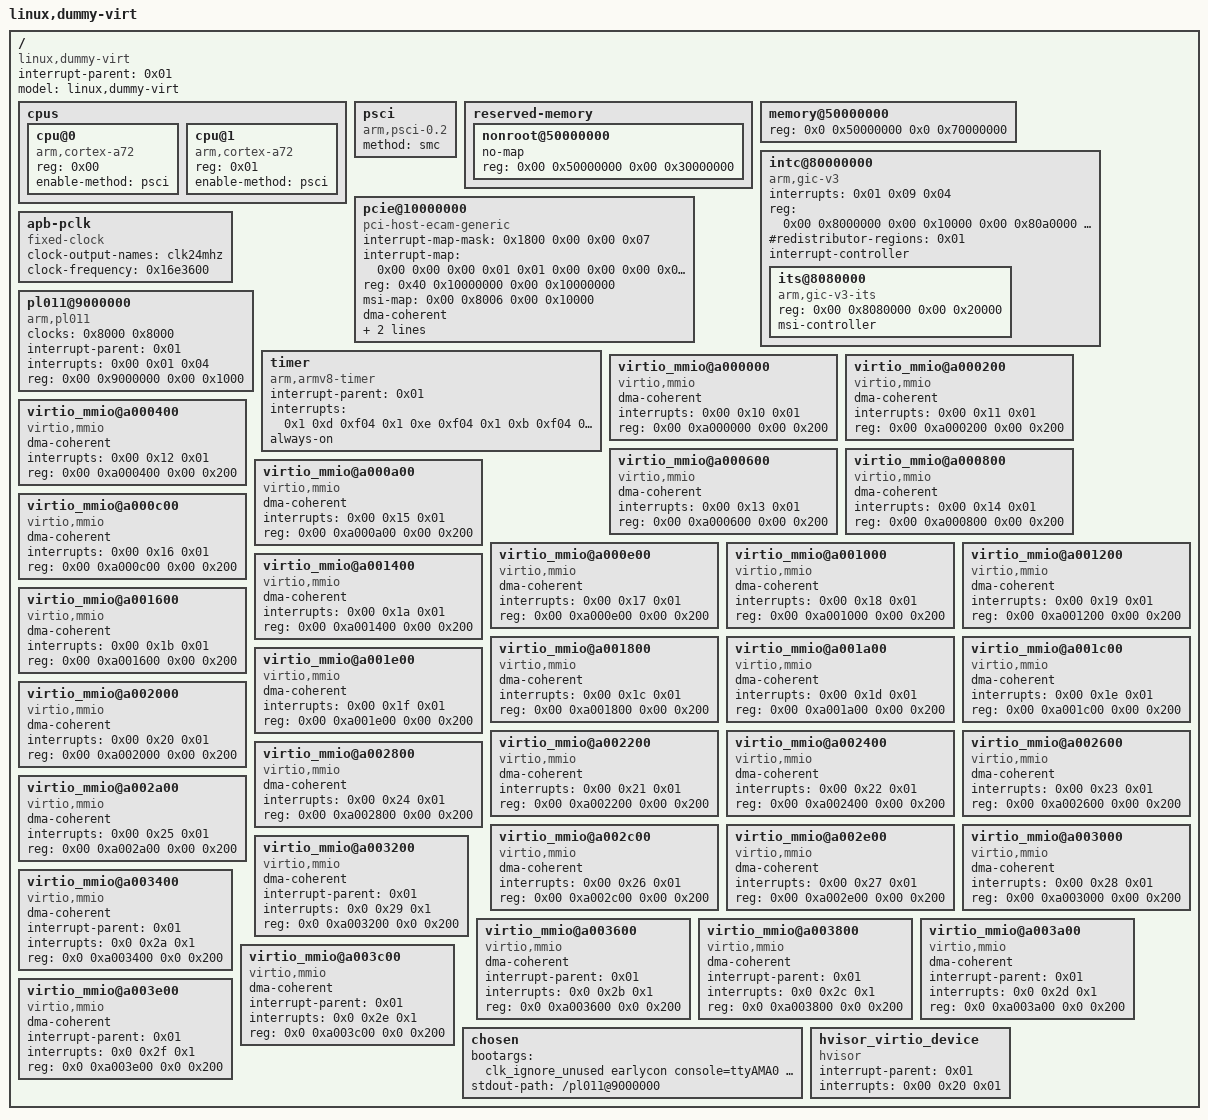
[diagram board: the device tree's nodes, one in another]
/dts-v1/;

/ {
	#size-cells = <0x2>;
	#address-cells = <0x2>;
	interrupt-parent = <0x01>;
	model = "linux,dummy-virt";
	compatible = "linux,dummy-virt";

	cpus {
		#size-cells = <0x00>;
		#address-cells = <0x01>;

		cpu@0 {
			phandle = <0x8010>;
			reg = <0x00>;
			enable-method = "psci";
			compatible = "arm,cortex-a72";
			device_type = "cpu";
		};

		cpu@1 {
			phandle = <0x800f>;
			reg = <0x01>;
			enable-method = "psci";
			compatible = "arm,cortex-a72";
			device_type = "cpu";
		};

	};

	psci {
		compatible = "arm,psci-0.2";
		method = "smc";
	};

	reserved-memory {
		#address-cells = <0x02>;
		#size-cells = <0x02>;
		ranges;

		nonroot@50000000 {
			no-map;
			reg = <0x00 0x50000000 0x00 0x30000000>;
		};
	};

	memory@50000000 {
		device_type = "memory";
		reg = <0x0 0x50000000 0x0 0x70000000>;
	};

	intc@80000000 {
		phandle = <0x01>;
		interrupts = <0x01 0x09 0x04>;
		reg = <0x00 0x8000000 0x00 0x10000 0x00 0x80a0000 0x00 0xf60000>;
		#redistributor-regions = <0x01>;
		compatible = "arm,gic-v3";
		ranges;
		#size-cells = <0x02>;
		#address-cells = <0x02>;
		interrupt-controller;
		#interrupt-cells = <0x03>;

		its@8080000 {
			phandle = <0x8006>;
			reg = <0x00 0x8080000 0x00 0x20000>;
			#msi-cells = <0x01>;
			msi-controller;
			compatible = "arm,gic-v3-its";
		};
	};

	pcie@10000000 {
		interrupt-map-mask = <0x1800 0x00 0x00 0x07>;
		interrupt-map = <0x00 0x00 0x00 0x01 0x01 0x00 0x00 0x00 0x03 0x04 0x00 0x00 0x00 0x02 0x01 0x00 0x00 0x00 0x04 0x04 0x00 0x00 0x00 0x03 0x01 0x00 0x00 0x00 0x05 0x04 0x00 0x00 0x00 0x04 0x01 0x00 0x00 0x00 0x06 0x04 0x800 0x00 0x00 0x01 0x01 0x00 0x00 0x00 0x04 0x04 0x800 0x00 0x00 0x02 0x01 0x00 0x00 0x00 0x05 0x04 0x800 0x00 0x00 0x03 0x01 0x00 0x00 0x00 0x06 0x04 0x800 0x00 0x00 0x04 0x01 0x00 0x00 0x00 0x03 0x04 0x1000 0x00 0x00 0x01 0x01 0x00 0x00 0x00 0x05 0x04 0x1000 0x00 0x00 0x02 0x01 0x00 0x00 0x00 0x06 0x04 0x1000 0x00 0x00 0x03 0x01 0x00 0x00 0x00 0x03 0x04 0x1000 0x00 0x00 0x04 0x01 0x00 0x00 0x00 0x04 0x04 0x1800 0x00 0x00 0x01 0x01 0x00 0x00 0x00 0x06 0x04 0x1800 0x00 0x00 0x02 0x01 0x00 0x00 0x00 0x03 0x04 0x1800 0x00 0x00 0x03 0x01 0x00 0x00 0x00 0x04 0x04 0x1800 0x00 0x00 0x04 0x01 0x00 0x00 0x00 0x05 0x04>;
		#interrupt-cells = <0x01>;
		ranges = <0x1000000 0x00 0x00 0x00 0x3eff0000 0x00 0x10000 
		0x2000000 0x00 0x10000000 0x00 0x10000000 0x00 0x2eff0000 
		0x3000000 0x80 0x00 0x80 0x00 0x80 0x00>;
		reg = <0x40 0x10000000 0x00 0x10000000>;
		msi-map = <0x00 0x8006 0x00 0x10000>;
		dma-coherent;
		bus-range = <0x00 0xff>;
		linux,pci-domain = <0x00>;
		#size-cells = <0x02>;
		#address-cells = <0x03>;
		device_type = "pci";
		compatible = "pci-host-ecam-generic";
	};

	apb-pclk {
		phandle = <0x8000>;
		clock-output-names = "clk24mhz";
		clock-frequency = <0x16e3600>;
		#clock-cells = <0x00>;
		compatible = "fixed-clock";
	};

	pl011@9000000 {
		clock-names = "uartclk\0apb_pclk";
		clocks = <0x8000 0x8000>;
		interrupt-parent = <0x01>;
		interrupts = <0x00 0x01 0x04>;
		reg = <0x00 0x9000000 0x00 0x1000>;
		compatible = "arm,pl011\0arm,primecell";
	};

	timer {
		interrupt-parent = <0x01>;
		interrupts = <0x1 0xd 0xf04 0x1 0xe 0xf04 0x1 0xb 0xf04 0x1 0xa 0xf04>;
		always-on;
		compatible = "arm,armv8-timer", "arm,armv7-timer";
	};

	virtio_mmio@a000000 {
		dma-coherent;
		interrupts = <0x00 0x10 0x01>;
		reg = <0x00 0xa000000 0x00 0x200>;
		compatible = "virtio,mmio";
	};

	virtio_mmio@a000200 {
		dma-coherent;
		interrupts = <0x00 0x11 0x01>;
		reg = <0x00 0xa000200 0x00 0x200>;
		compatible = "virtio,mmio";
	};

	virtio_mmio@a000400 {
		dma-coherent;
		interrupts = <0x00 0x12 0x01>;
		reg = <0x00 0xa000400 0x00 0x200>;
		compatible = "virtio,mmio";
	};

	virtio_mmio@a000600 {
		dma-coherent;
		interrupts = <0x00 0x13 0x01>;
		reg = <0x00 0xa000600 0x00 0x200>;
		compatible = "virtio,mmio";
	};

	virtio_mmio@a000800 {
		dma-coherent;
		interrupts = <0x00 0x14 0x01>;
		reg = <0x00 0xa000800 0x00 0x200>;
		compatible = "virtio,mmio";
	};

	virtio_mmio@a000a00 {
		dma-coherent;
		interrupts = <0x00 0x15 0x01>;
		reg = <0x00 0xa000a00 0x00 0x200>;
		compatible = "virtio,mmio";
	};

	virtio_mmio@a000c00 {
		dma-coherent;
		interrupts = <0x00 0x16 0x01>;
		reg = <0x00 0xa000c00 0x00 0x200>;
		compatible = "virtio,mmio";
	};

	virtio_mmio@a000e00 {
		dma-coherent;
		interrupts = <0x00 0x17 0x01>;
		reg = <0x00 0xa000e00 0x00 0x200>;
		compatible = "virtio,mmio";
	};

	virtio_mmio@a001000 {
		dma-coherent;
		interrupts = <0x00 0x18 0x01>;
		reg = <0x00 0xa001000 0x00 0x200>;
		compatible = "virtio,mmio";
	};

	virtio_mmio@a001200 {
		dma-coherent;
		interrupts = <0x00 0x19 0x01>;
		reg = <0x00 0xa001200 0x00 0x200>;
		compatible = "virtio,mmio";
	};

	virtio_mmio@a001400 {
		dma-coherent;
		interrupts = <0x00 0x1a 0x01>;
		reg = <0x00 0xa001400 0x00 0x200>;
		compatible = "virtio,mmio";
	};

	virtio_mmio@a001600 {
		dma-coherent;
		interrupts = <0x00 0x1b 0x01>;
		reg = <0x00 0xa001600 0x00 0x200>;
		compatible = "virtio,mmio";
	};

	virtio_mmio@a001800 {
		dma-coherent;
		interrupts = <0x00 0x1c 0x01>;
		reg = <0x00 0xa001800 0x00 0x200>;
		compatible = "virtio,mmio";
	};

	virtio_mmio@a001a00 {
		dma-coherent;
		interrupts = <0x00 0x1d 0x01>;
		reg = <0x00 0xa001a00 0x00 0x200>;
		compatible = "virtio,mmio";
	};

	virtio_mmio@a001c00 {
		dma-coherent;
		interrupts = <0x00 0x1e 0x01>;
		reg = <0x00 0xa001c00 0x00 0x200>;
		compatible = "virtio,mmio";
	};

	virtio_mmio@a001e00 {
		dma-coherent;
		interrupts = <0x00 0x1f 0x01>;
		reg = <0x00 0xa001e00 0x00 0x200>;
		compatible = "virtio,mmio";
	};

	virtio_mmio@a002000 {
		dma-coherent;
		interrupts = <0x00 0x20 0x01>;
		reg = <0x00 0xa002000 0x00 0x200>;
		compatible = "virtio,mmio";
	};

	virtio_mmio@a002200 {
		dma-coherent;
		interrupts = <0x00 0x21 0x01>;
		reg = <0x00 0xa002200 0x00 0x200>;
		compatible = "virtio,mmio";
	};

	virtio_mmio@a002400 {
		dma-coherent;
		interrupts = <0x00 0x22 0x01>;
		reg = <0x00 0xa002400 0x00 0x200>;
		compatible = "virtio,mmio";
	};

	virtio_mmio@a002600 {
		dma-coherent;
		interrupts = <0x00 0x23 0x01>;
		reg = <0x00 0xa002600 0x00 0x200>;
		compatible = "virtio,mmio";
	};

	virtio_mmio@a002800 {
		dma-coherent;
		interrupts = <0x00 0x24 0x01>;
		reg = <0x00 0xa002800 0x00 0x200>;
		compatible = "virtio,mmio";
	};

	virtio_mmio@a002a00 {
		dma-coherent;
		interrupts = <0x00 0x25 0x01>;
		reg = <0x00 0xa002a00 0x00 0x200>;
		compatible = "virtio,mmio";
	};

	virtio_mmio@a002c00 {
		dma-coherent;
		interrupts = <0x00 0x26 0x01>;
		reg = <0x00 0xa002c00 0x00 0x200>;
		compatible = "virtio,mmio";
	};

	virtio_mmio@a002e00 {
		dma-coherent;
		interrupts = <0x00 0x27 0x01>;
		reg = <0x00 0xa002e00 0x00 0x200>;
		compatible = "virtio,mmio";
	};

	virtio_mmio@a003000 {
		dma-coherent;
		interrupts = <0x00 0x28 0x01>;
		reg = <0x00 0xa003000 0x00 0x200>;
		compatible = "virtio,mmio";
	};

	virtio_mmio@a003200 {
		dma-coherent;
	 interrupt-parent = <0x01>;
		interrupts = <0x0 0x29 0x1>;
		reg = <0x0 0xa003200 0x0 0x200>;
		compatible = "virtio,mmio";
	};

	virtio_mmio@a003400 {
		dma-coherent;
	 interrupt-parent = <0x01>;
		interrupts = <0x0 0x2a 0x1>;
		reg = <0x0 0xa003400 0x0 0x200>;
		compatible = "virtio,mmio";
	};

	virtio_mmio@a003600 {
		dma-coherent;
		interrupt-parent = <0x01>;
		interrupts = <0x0 0x2b 0x1>;
		reg = <0x0 0xa003600 0x0 0x200>;
		compatible = "virtio,mmio";
	};

	virtio_mmio@a003800 {
		dma-coherent;
	 interrupt-parent = <0x01>;
		interrupts = <0x0 0x2c 0x1>;
		reg = <0x0 0xa003800 0x0 0x200>;
		compatible = "virtio,mmio";
	};

	virtio_mmio@a003a00 {
		dma-coherent;
		interrupt-parent = <0x01>;
		interrupts = <0x0 0x2d 0x1>;
		reg = <0x0 0xa003a00 0x0 0x200>;
		compatible = "virtio,mmio";
	};

	virtio_mmio@a003c00 {
		dma-coherent;
	 interrupt-parent = <0x01>;
		interrupts = <0x0 0x2e 0x1>;
		reg = <0x0 0xa003c00 0x0 0x200>;
		compatible = "virtio,mmio";
	};

	// virtio disk
	virtio_mmio@a003e00 {
		dma-coherent;
		interrupt-parent = <0x01>;
		interrupts = <0x0 0x2f 0x1>;
		reg = <0x0 0xa003e00 0x0 0x200>;
		compatible = "virtio,mmio";
	};

	chosen {
		bootargs = "clk_ignore_unused earlycon console=ttyAMA0 root=/dev/vda iomem=relaxed rw";
        // bootargs = "root=/dev/vda mem=768M";
		stdout-path = "/pl011@9000000";
	};

	hvisor_virtio_device {
		compatible = "hvisor";
		interrupt-parent = <0x01>;
		interrupts = <0x00 0x20 0x01>;
	};
};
